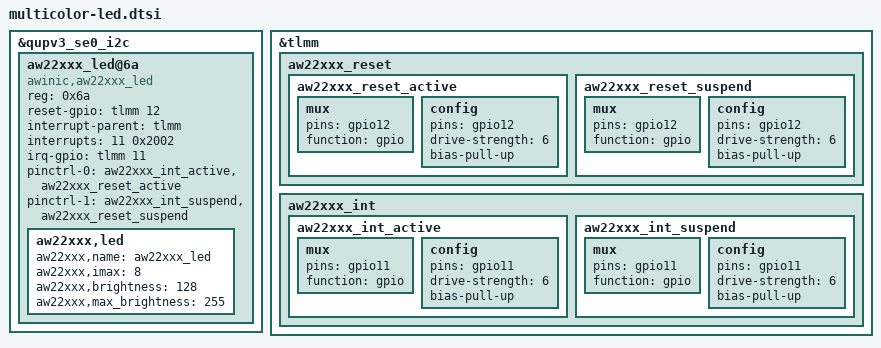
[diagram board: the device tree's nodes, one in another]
/* Copyright (c) 2016-2017, The Linux Foundation. All rights reserved.
 *
 * This program is free software; you can redistribute it and/or modify
 * it under the terms of the GNU General Public License version 2 and
 * only version 2 as published by the Free Software Foundation.
 *
 * This program is distributed in the hope that it will be useful,
 * but WITHOUT ANY WARRANTY; without even the implied warranty of
 * MERCHANTABILITY or FITNESS FOR A PARTICULAR PURPOSE.  See the
 * GNU General Public License for more details.
 */

&qupv3_se0_i2c {
	status = "okay";
	aw22xxx_led@6a {
		status = "okay";
		compatible = "awinic,aw22xxx_led";
		reg = <0x6a>;
		reset-gpio = <&tlmm 12 0x0>;
		interrupt-parent = <&tlmm>;
		interrupts = <11 0x2002>;
		irq-gpio = <&tlmm 11 0x2002>;
		pinctrl-names = "aw22xxx_led_default", "aw22xxx_led_sleep";
		pinctrl-0 = <&aw22xxx_int_active &aw22xxx_reset_active>;
		pinctrl-1 = <&aw22xxx_int_suspend &aw22xxx_reset_suspend>;
		aw22xxx,led {
			aw22xxx,name = "aw22xxx_led";
			aw22xxx,imax = <8>;
			aw22xxx,brightness = <128>;
			aw22xxx,max_brightness = <255>;
		};
	};
};

&tlmm {
	aw22xxx_reset {
		aw22xxx_reset_active: aw22xxx_reset_active {
			mux {
				pins = "gpio12";
				function = "gpio";
			};
			config {
				pins = "gpio12";
				drive-strength = <6>;
				bias-pull-up;
			};
		};
		aw22xxx_reset_suspend: aw22xxx_reset_suspend {
			mux {
				pins = "gpio12";
				function = "gpio";
			};
			config {
				pins = "gpio12";
				drive-strength = <6>;
				bias-pull-up;
			};
		};
	};

	aw22xxx_int {
		aw22xxx_int_active: aw22xxx_int_active {
			mux {
				pins = "gpio11";
				function = "gpio";
			};
			config {
				pins = "gpio11";
				drive-strength = <6>;
				bias-pull-up;
			};
		};
		aw22xxx_int_suspend: aw22xxx_int_suspend {
			mux {
				pins = "gpio11";
				function = "gpio";
			};
			config {
				pins = "gpio11";
				drive-strength = <6>;
				bias-pull-up;
			};
		};
	};
};

